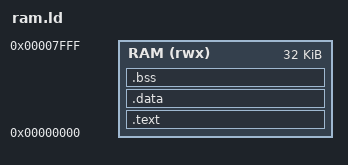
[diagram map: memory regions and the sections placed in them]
OUTPUT_ARCH(riscv)
ENTRY(_start)

MEMORY
{
  RAM (rwx) : ORIGIN = 0x00000000, LENGTH = 32K
}

SECTIONS
{
  .text : {
    KEEP(*(.text.start))
    *(.text .text.*)
    *(.rodata .rodata.*)
  } > RAM

  .data : {
    *(.data .data.*)
    *(.sdata .sdata.*)
  } > RAM

  .bss : {
    . = ALIGN(4);
    _bss_start = .;
    *(.bss .bss.*)
    *(.sbss .sbss.*)
    *(COMMON)
    . = ALIGN(4);
    _bss_end = .;
  } > RAM

  _stack_top = ORIGIN(RAM) + LENGTH(RAM);
}
